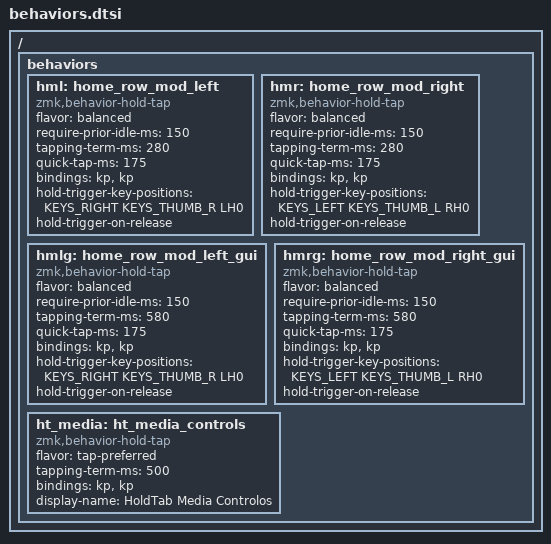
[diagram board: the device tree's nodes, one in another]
#define HML(KEY1, KEY2, KEY3, KEY4)  &hmlg LGUI KEY1   &hml LALT KEY2   &hml LCTRL KEY3  &hml LSHFT KEY4 
#define HMR(KEY1, KEY2, KEY3, KEY4)  &hmr  RSHFT KEY1  &hmr RCTRL KEY2  &hmr RALT KEY3   &hmrg RGUI KEY4 
#define HML3(KEY1, KEY2, KEY3)       &hml LALT KEY1    &hml LCTRL KEY2  &hml LSHFT KEY3 
#define HMR3(KEY1, KEY2, KEY3)       &hmr RSHFT KEY1   &hmr RCTRL KEY2  &hmr RALT KEY3

/ {
    behaviors {

        hml: home_row_mod_left {
            compatible = "zmk,behavior-hold-tap";
            #binding-cells = <2>;
            flavor = "balanced";
            require-prior-idle-ms = <150>;
            tapping-term-ms = <280>;
            quick-tap-ms = <175>;
            bindings = <&kp>, <&kp>;
            hold-trigger-key-positions = <KEYS_RIGHT KEYS_THUMB_R LH0>;
            hold-trigger-on-release;
        };
        hmr: home_row_mod_right {
            compatible = "zmk,behavior-hold-tap";
            #binding-cells = <2>;
            flavor = "balanced";
            require-prior-idle-ms = <150>;
            tapping-term-ms = <280>;
            quick-tap-ms = <175>;
            bindings = <&kp>, <&kp>;
            hold-trigger-key-positions = <KEYS_LEFT KEYS_THUMB_L RH0>;
            hold-trigger-on-release;
        };
        hmlg: home_row_mod_left_gui {
            compatible = "zmk,behavior-hold-tap";
            #binding-cells = <2>;
            flavor = "balanced";
            require-prior-idle-ms = <150>;
            tapping-term-ms = <580>;
            quick-tap-ms = <175>;
            bindings = <&kp>, <&kp>;
            hold-trigger-key-positions = <KEYS_RIGHT KEYS_THUMB_R LH0>;
            hold-trigger-on-release;
        };
        hmrg: home_row_mod_right_gui {
            compatible = "zmk,behavior-hold-tap";
            #binding-cells = <2>;
            flavor = "balanced";
            require-prior-idle-ms = <150>;
            tapping-term-ms = <580>;
            quick-tap-ms = <175>;
            bindings = <&kp>, <&kp>;
            hold-trigger-key-positions = <KEYS_LEFT KEYS_THUMB_L RH0>;
            hold-trigger-on-release;
        };

        ht_media: ht_media_controls {
            compatible = "zmk,behavior-hold-tap";
            #binding-cells = <2>;
            flavor = "tap-preferred";
            tapping-term-ms = <500>;
            bindings = <&kp>, <&kp>;
            display-name = "HoldTab Media Controlos";
        };
    };
};

